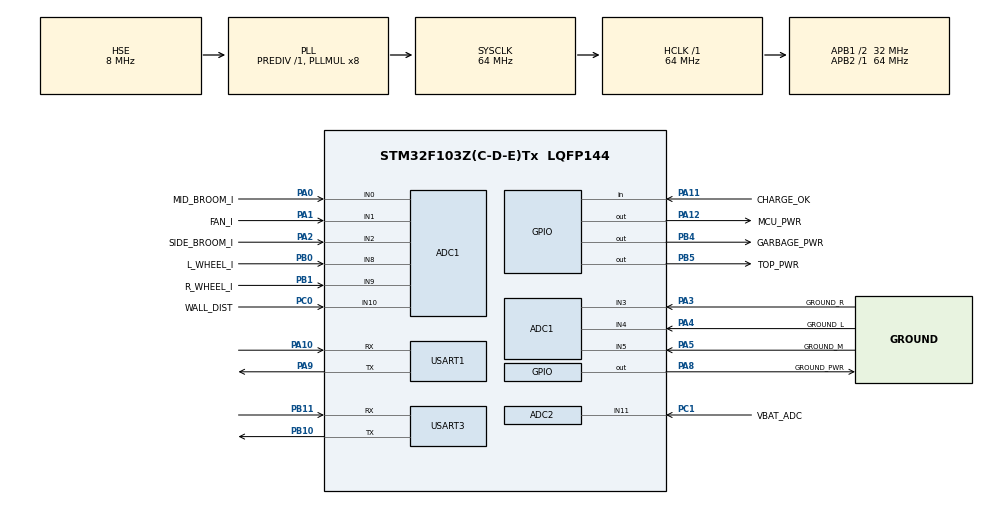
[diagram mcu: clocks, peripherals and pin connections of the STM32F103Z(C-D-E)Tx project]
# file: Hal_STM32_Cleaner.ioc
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ADC1.Channel-0\#ChannelRegularConversion=ADC_CHANNEL_VREFINT
ADC1.Channel-1\#ChannelRegularConversion=ADC_CHANNEL_TEMPSENSOR
ADC1.Channel-10\#ChannelRegularConversion=ADC_CHANNEL_10
ADC1.Channel-2\#ChannelRegularConversion=ADC_CHANNEL_0
ADC1.Channel-3\#ChannelRegularConversion=ADC_CHANNEL_1
ADC1.Channel-4\#ChannelRegularConversion=ADC_CHANNEL_2
ADC1.Channel-5\#ChannelRegularConversion=ADC_CHANNEL_3
ADC1.Channel-6\#ChannelRegularConversion=ADC_CHANNEL_4
ADC1.Channel-7\#ChannelRegularConversion=ADC_CHANNEL_5
ADC1.Channel-8\#ChannelRegularConversion=ADC_CHANNEL_8
ADC1.Channel-9\#ChannelRegularConversion=ADC_CHANNEL_9
ADC1.ContinuousConvMode=ENABLE
ADC1.DataAlign=ADC_DATAALIGN_RIGHT
ADC1.DiscontinuousConvMode=DISABLE
ADC1.EnableAnalogWatchDog=false
ADC1.EnableRegularConversion=ENABLE
ADC1.ExternalTrigConv=ADC_SOFTWARE_START
ADC1.InjNumberOfConversion=0
ADC1.NbrOfConversion=11
ADC1.NbrOfConversionFlag=1
ADC1.Rank-0\#ChannelRegularConversion=1
ADC1.Rank-1\#ChannelRegularConversion=2
ADC1.Rank-10\#ChannelRegularConversion=11
ADC1.Rank-2\#ChannelRegularConversion=3
ADC1.Rank-3\#ChannelRegularConversion=4
ADC1.Rank-4\#ChannelRegularConversion=5
ADC1.Rank-5\#ChannelRegularConversion=6
ADC1.Rank-6\#ChannelRegularConversion=7
ADC1.Rank-7\#ChannelRegularConversion=8
ADC1.Rank-8\#ChannelRegularConversion=9
ADC1.Rank-9\#ChannelRegularConversion=10
ADC1.SamplingTime-0\#ChannelRegularConversion=ADC_SAMPLETIME_55CYCLES_5
ADC1.SamplingTime-1\#ChannelRegularConversion=ADC_SAMPLETIME_55CYCLES_5
ADC1.SamplingTime-10\#ChannelRegularConversion=ADC_SAMPLETIME_55CYCLES_5
ADC1.SamplingTime-2\#ChannelRegularConversion=ADC_SAMPLETIME_55CYCLES_5
ADC1.SamplingTime-3\#ChannelRegularConversion=ADC_SAMPLETIME_55CYCLES_5
ADC1.SamplingTime-4\#ChannelRegularConversion=ADC_SAMPLETIME_55CYCLES_5
ADC1.SamplingTime-5\#ChannelRegularConversion=ADC_SAMPLETIME_55CYCLES_5
ADC1.SamplingTime-6\#ChannelRegularConversion=ADC_SAMPLETIME_55CYCLES_5
ADC1.SamplingTime-7\#ChannelRegularConversion=ADC_SAMPLETIME_55CYCLES_5
ADC1.SamplingTime-8\#ChannelRegularConversion=ADC_SAMPLETIME_55CYCLES_5
ADC1.SamplingTime-9\#ChannelRegularConversion=ADC_SAMPLETIME_55CYCLES_5
ADC1.ScanConvMode=ADC_SCAN_ENABLE
ADC1.master=1
ADC2.Channel-5\#ChannelRegularConversion=ADC_CHANNEL_11
ADC2.ContinuousConvMode=ENABLE
ADC2.NbrOfConversionFlag=1
ADC2.Rank-5\#ChannelRegularConversion=1
ADC2.SamplingTime-5\#ChannelRegularConversion=ADC_SAMPLETIME_71CYCLES_5
Dma.ADC1.4.Direction=DMA_PERIPH_TO_MEMORY
Dma.ADC1.4.Instance=DMA1_Channel1
Dma.ADC1.4.MemDataAlignment=DMA_MDATAALIGN_HALFWORD
Dma.ADC1.4.MemInc=DMA_MINC_ENABLE
Dma.ADC1.4.Mode=DMA_CIRCULAR
Dma.ADC1.4.PeriphDataAlignment=DMA_PDATAALIGN_HALFWORD
Dma.ADC1.4.PeriphInc=DMA_PINC_DISABLE
Dma.ADC1.4.Priority=DMA_PRIORITY_VERY_HIGH
Dma.Request0=USART1_RX
Dma.Request1=USART1_TX
Dma.Request2=USART3_RX
Dma.Request3=USART3_TX
Dma.Request4=ADC1
Dma.USART1_RX.0.Direction=DMA_PERIPH_TO_MEMORY
Dma.USART1_RX.0.Instance=DMA1_Channel5
Dma.USART1_RX.0.MemDataAlignment=DMA_MDATAALIGN_BYTE
Dma.USART1_RX.0.MemInc=DMA_MINC_ENABLE
Dma.USART1_RX.0.Mode=DMA_NORMAL
Dma.USART1_RX.0.PeriphDataAlignment=DMA_PDATAALIGN_BYTE
Dma.USART1_RX.0.PeriphInc=DMA_PINC_DISABLE
Dma.USART1_RX.0.Priority=DMA_PRIORITY_HIGH
Dma.USART1_TX.1.Direction=DMA_MEMORY_TO_PERIPH
Dma.USART1_TX.1.Instance=DMA1_Channel4
Dma.USART1_TX.1.MemDataAlignment=DMA_MDATAALIGN_BYTE
Dma.USART1_TX.1.MemInc=DMA_MINC_ENABLE
Dma.USART1_TX.1.Mode=DMA_NORMAL
Dma.USART1_TX.1.PeriphDataAlignment=DMA_PDATAALIGN_BYTE
Dma.USART1_TX.1.PeriphInc=DMA_PINC_DISABLE
Dma.USART1_TX.1.Priority=DMA_PRIORITY_MEDIUM
Dma.USART3_RX.2.Direction=DMA_PERIPH_TO_MEMORY
Dma.USART3_RX.2.Instance=DMA1_Channel3
Dma.USART3_RX.2.MemDataAlignment=DMA_MDATAALIGN_BYTE
Dma.USART3_RX.2.MemInc=DMA_MINC_ENABLE
Dma.USART3_RX.2.Mode=DMA_NORMAL
Dma.USART3_RX.2.PeriphDataAlignment=DMA_PDATAALIGN_BYTE
Dma.USART3_RX.2.PeriphInc=DMA_PINC_DISABLE
Dma.USART3_RX.2.Priority=DMA_PRIORITY_HIGH
Dma.USART3_TX.3.Direction=DMA_MEMORY_TO_PERIPH
Dma.USART3_TX.3.Instance=DMA1_Channel2
Dma.USART3_TX.3.MemDataAlignment=DMA_MDATAALIGN_BYTE
Dma.USART3_TX.3.MemInc=DMA_MINC_ENABLE
Dma.USART3_TX.3.Mode=DMA_NORMAL
Dma.USART3_TX.3.PeriphDataAlignment=DMA_PDATAALIGN_BYTE
Dma.USART3_TX.3.PeriphInc=DMA_PINC_DISABLE
Dma.USART3_TX.3.Priority=DMA_PRIORITY_MEDIUM
Mcu.Family=STM32F1
Mcu.Name=STM32F103Z(C-D-E)Tx
Mcu.Package=LQFP144
Mcu.UserConstants=CKTIM_APB1,64000000;CKTIM_APB2,64000000;PWM_ALIGN_FACTOR,1;PWM_PRSC,0;PWM_CNT_FREQ,(CKTIM_APB2 / PWM_ALIGN_FACTOR / (PWM_PRSC + 1));PWM_FREQ,20000;PWM_PERIOD,(PWM_CNT_FREQ / PWM_FREQ);ENCODER_PERIOD,4096
NVIC.DMA1_Channel1_IRQn=true\:0\:0\:false\:false\:true
NVIC.DMA1_Channel2_IRQn=true\:0\:0\:false\:false\:true
NVIC.DMA1_Channel3_IRQn=true\:0\:0\:false\:false\:true
NVIC.DMA1_Channel4_IRQn=true\:0\:0\:false\:false\:true
NVIC.DMA1_Channel5_IRQn=true\:0\:0\:false\:false\:true
NVIC.PriorityGroup=NVIC_PRIORITYGROUP_4
OSC_IN.Mode=HSE-External-Oscillator
OSC_IN.Signal=RCC_OSC_IN
OSC_OUT.Mode=HSE-External-Oscillator
OSC_OUT.Signal=RCC_OSC_OUT
PA0-WKUP.GPIO_Label=MID_BROOM_I
PA0-WKUP.Signal=ADCx_IN0
PA1.GPIO_Label=FAN_I
PA1.Signal=ADCx_IN1
PA10.Mode=Asynchronous
PA10.Signal=USART1_RX
PA11.GPIO_Label=CHARGE_OK
PA11.Signal=GPIO_Input
PA12.GPIO_Label=MCU_PWR
PA12.Signal=GPIO_Output
PA13.Mode=Serial_Wire
PA13.Signal=SYS_JTMS-SWDIO
PA14.Mode=Serial_Wire
PA14.Signal=SYS_JTCK-SWCLK
PA2.GPIO_Label=SIDE_BROOM_I
PA2.Signal=ADCx_IN2
PA3.GPIO_Label=GROUND_R
PA3.Signal=ADCx_IN3
PA4.GPIO_Label=GROUND_L
PA4.Signal=ADCx_IN4
PA5.GPIO_Label=GROUND_M
PA5.Signal=ADCx_IN5
PA8.GPIO_Label=GROUND_PWR
PA8.GPIO_ModeDefaultOutputPP=GPIO_MODE_OUTPUT_OD
PA8.Signal=GPIO_Output
PA9.Mode=Asynchronous
PA9.Signal=USART1_TX
PB0.GPIO_Label=L_WHEEL_I
PB0.Signal=ADCx_IN8
PB1.GPIO_Label=R_WHEEL_I
PB1.Signal=ADCx_IN9
PB10.Mode=Asynchronous
PB10.Signal=USART3_TX
PB11.Mode=Asynchronous
PB11.Signal=USART3_RX
PB4.GPIO_Label=GARBAGE_PWR
PB4.GPIO_ModeDefaultOutputPP=GPIO_MODE_OUTPUT_OD
PB4.Signal=GPIO_Output
PB5.GPIO_Label=TOP_PWR
PB5.Signal=GPIO_Output
PC0.GPIO_Label=WALL_DIST
PC0.Signal=ADCx_IN10
PC1.GPIO_Label=VBAT_ADC
PC1.Signal=ADCx_IN11
ProjectManager.HeapSize=0x200
ProjectManager.StackSize=0x400
ProjectManager.TargetToolchain=MDK-ARM V5
RCC.ADCPresc=RCC_ADCPCLK2_DIV6
RCC.AHBFreq_Value=64000000
RCC.APB1CLKDivider=RCC_HCLK_DIV2
RCC.APB1Freq_Value=32000000
RCC.APB1TimFreq_Value=64000000
RCC.APB2Freq_Value=64000000
RCC.APB2TimFreq_Value=64000000
RCC.HCLKFreq_Value=64000000
RCC.PLLMUL=RCC_PLL_MUL8
RCC.PLLSourceVirtual=RCC_PLLSOURCE_HSE
RCC.SYSCLKFreq_VALUE=64000000
RCC.SYSCLKSource=RCC_SYSCLKSOURCE_PLLCLK
RCC.USBFreq_Value=64000000
SH.ADCx_IN0.0=ADC1_IN0,IN0
SH.ADCx_IN1.0=ADC1_IN1,IN1
SH.ADCx_IN10.0=ADC1_IN10,IN10
SH.ADCx_IN11.0=ADC2_IN11,IN11
SH.ADCx_IN2.0=ADC1_IN2,IN2
SH.ADCx_IN3.0=ADC1_IN3,IN3
SH.ADCx_IN4.0=ADC1_IN4,IN4
SH.ADCx_IN5.0=ADC1_IN5,IN5
SH.ADCx_IN8.0=ADC1_IN8,IN8
SH.ADCx_IN9.0=ADC1_IN9,IN9
USART1.VirtualMode=VM_ASYNC
USART3.VirtualMode=VM_ASYNC
VP_ADC1_TempSens_Input.Mode=IN-TempSens
VP_ADC1_Vref_Input.Mode=IN-Vrefint
VP_CRC_VS_CRC.Mode=CRC_Activate
board=Hal_STM32_Cleaner

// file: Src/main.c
/**
  ******************************************************************************
  * File Name          : main.c
  * Description        : Main program body
  ******************************************************************************
  ** This notice applies to any and all portions of this file
  * that are not between comment pairs USER CODE BEGIN and
  * USER CODE END. Other portions of this file, whether
  * inserted by the user or by software development tools
  * are owned by their respective copyright owners.
  *
  * COPYRIGHT(c) 2017 STMicroelectronics
  *
  * Redistribution and use in source and binary forms, with or without modification,
  * are permitted provided that the following conditions are met:
  *   1. Redistributions of source code must retain the above copyright notice,
  *      this list of conditions and the following disclaimer.
  *   2. Redistributions in binary form must reproduce the above copyright notice,
  *      this list of conditions and the following disclaimer in the documentation
  *      and/or other materials provided with the distribution.
  *   3. Neither the name of STMicroelectronics nor the names of its contributors
  *      may be used to endorse or promote products derived from this software
  *      without specific prior written permission.
  *
  * THIS SOFTWARE IS PROVIDED BY THE COPYRIGHT HOLDERS AND CONTRIBUTORS "AS IS"
  * AND ANY EXPRESS OR IMPLIED WARRANTIES, INCLUDING, BUT NOT LIMITED TO, THE
  * IMPLIED WARRANTIES OF MERCHANTABILITY AND FITNESS FOR A PARTICULAR PURPOSE ARE
  * DISCLAIMED. IN NO EVENT SHALL THE COPYRIGHT HOLDER OR CONTRIBUTORS BE LIABLE
  * FOR ANY DIRECT, INDIRECT, INCIDENTAL, SPECIAL, EXEMPLARY, OR CONSEQUENTIAL
  * DAMAGES (INCLUDING, BUT NOT LIMITED TO, PROCUREMENT OF SUBSTITUTE GOODS OR
  * SERVICES; LOSS OF USE, DATA, OR PROFITS; OR BUSINESS INTERRUPTION) HOWEVER
  * CAUSED AND ON ANY THEORY OF LIABILITY, WHETHER IN CONTRACT, STRICT LIABILITY,
  * OR TORT (INCLUDING NEGLIGENCE OR OTHERWISE) ARISING IN ANY WAY OUT OF THE USE
  * OF THIS SOFTWARE, EVEN IF ADVISED OF THE POSSIBILITY OF SUCH DAMAGE.
  *
  ******************************************************************************
  */
#include "main.h"
#include "stm32f1xx_hal.h"
#include "adc.h"
#include "crc.h"
#include "dma.h"
#include "usart.h"
#include "gpio.h"

/* USER CODE BEGIN Includes */
#include "bsp.h"
#include "comm.h"
#include "bsp_usart.h"
/* USER CODE END Includes */

/* USER CODE BEGIN PV */
/* Private variables ---------------------------------------------------------*/
UART_HandleTypeDef UartHandle;

/* Buffer used for transmission */
uint8_t aTxBuffer[] = "\n\r ****UART-Hyperterminal communication based on DMA****\n\r Enter 10 characters using keyboard :\n\r";

/* Buffer used for reception */
uint8_t aRxBuffer[50];

/* USER CODE END PV */

void SystemClock_Config(void);

/* USER CODE BEGIN PFP */
/* Private function prototypes -----------------------------------------------*/

/* USER CODE END PFP */

int main(void)
{

  /* MCU Configuration----------------------------------------------------------*/

  /* Reset of all peripherals, Initializes the Flash interface and the Systick. */
  HAL_Init();

  /* Configure the system clock */
  SystemClock_Config();

  /* Initialize all configured peripherals */
  MX_GPIO_Init();
  MX_DMA_Init();
  MX_USART1_UART_Init();
  MX_USART3_UART_Init();
  MX_CRC_Init();
  MX_ADC1_Init();
  MX_ADC2_Init();

  /* USER CODE BEGIN 2 */

	Bsp_Init();

	send_test();
  /* USER CODE END 2 */

  /* Infinite loop */
  /* USER CODE BEGIN WHILE */
	if (HAL_UART_Init(&huart1) != HAL_OK)
	{
		/* Initialization Error */
		Error_Handler();
	}

	/*##-2- Start the transmission process #####################################*/
	/* User start transmission data through "TxBuffer" buffer */
//	if (HAL_UART_Transmit_DMA(&huart1, (uint8_t *)aTxBuffer, sizeof(aTxBuffer)) != HAL_OK)
//	{
//	/* Transfer error in transmission process */
//		Error_Handler();
//	}

	UserUsart_SendData(&CommUsart, (uint8_t *)aTxBuffer, sizeof(aTxBuffer));

	while (1)
	{
  /* USER CODE END WHILE */

	}

}

/** System Clock Configuration
*/
void SystemClock_Config(void)
{

  RCC_OscInitTypeDef RCC_OscInitStruct;
  RCC_ClkInitTypeDef RCC_ClkInitStruct;
  RCC_PeriphCLKInitTypeDef PeriphClkInit;

    /**Initializes the CPU, AHB and APB busses clocks
    */
  RCC_OscInitStruct.OscillatorType = RCC_OSCILLATORTYPE_HSE;
  RCC_OscInitStruct.HSEState = RCC_HSE_ON;
  RCC_OscInitStruct.HSEPredivValue = RCC_HSE_PREDIV_DIV1;
  RCC_OscInitStruct.HSIState = RCC_HSI_ON;
  RCC_OscInitStruct.PLL.PLLState = RCC_PLL_ON;
  RCC_OscInitStruct.PLL.PLLSource = RCC_PLLSOURCE_HSE;
  RCC_OscInitStruct.PLL.PLLMUL = RCC_PLL_MUL8;
  if (HAL_RCC_OscConfig(&RCC_OscInitStruct) != HAL_OK)
  {
    _Error_Handler(__FILE__, __LINE__);
  }

    /**Initializes the CPU, AHB and APB busses clocks
    */
  RCC_ClkInitStruct.ClockType = RCC_CLOCKTYPE_HCLK|RCC_CLOCKTYPE_SYSCLK
                              |RCC_CLOCKTYPE_PCLK1|RCC_CLOCKTYPE_PCLK2;
  RCC_ClkInitStruct.SYSCLKSource = RCC_SYSCLKSOURCE_PLLCLK;
  RCC_ClkInitStruct.AHBCLKDivider = RCC_SYSCLK_DIV1;
  RCC_ClkInitStruct.APB1CLKDivider = RCC_HCLK_DIV2;
  RCC_ClkInitStruct.APB2CLKDivider = RCC_HCLK_DIV1;

  if (HAL_RCC_ClockConfig(&RCC_ClkInitStruct, FLASH_LATENCY_2) != HAL_OK)
  {
    _Error_Handler(__FILE__, __LINE__);
  }

  PeriphClkInit.PeriphClockSelection = RCC_PERIPHCLK_ADC;
  PeriphClkInit.AdcClockSelection = RCC_ADCPCLK2_DIV6;
  if (HAL_RCCEx_PeriphCLKConfig(&PeriphClkInit) != HAL_OK)
  {
    _Error_Handler(__FILE__, __LINE__);
  }

    /**Configure the Systick interrupt time
    */
  HAL_SYSTICK_Config(HAL_RCC_GetHCLKFreq()/1000);

    /**Configure the Systick
    */
  HAL_SYSTICK_CLKSourceConfig(SYSTICK_CLKSOURCE_HCLK);

  /* SysTick_IRQn interrupt configuration */
  HAL_NVIC_SetPriority(SysTick_IRQn, 0, 0);
}

void _Error_Handler(char * file, int line)
{
  while(1)
  {
  }
}

/************************ (C) COPYRIGHT STMicroelectronics *****END OF FILE****/
